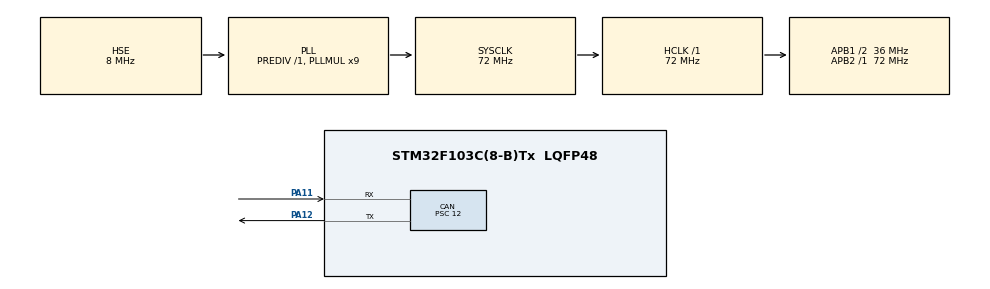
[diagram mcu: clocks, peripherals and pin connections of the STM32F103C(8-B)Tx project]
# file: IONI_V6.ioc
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CAN.CalculateBaudRate=999999
CAN.CalculateTimeBit=1000
CAN.CalculateTimeQuantum=333.33333333333337
CAN.Mode=CAN_MODE_NORMAL
CAN.Prescaler=12
Mcu.Family=STM32F1
Mcu.Name=STM32F103C(8-B)Tx
Mcu.Package=LQFP48
NVIC.CAN1_RX1_IRQn=true\:0\:0\:false\:false\:true\:true\:true\:true
NVIC.PriorityGroup=NVIC_PRIORITYGROUP_4
NVIC.USB_LP_CAN1_RX0_IRQn=true\:0\:0\:false\:false\:true\:true\:true\:true
PA11.Mode=CAN_Activate
PA11.Signal=CAN_RX
PA12.Mode=CAN_Activate
PA12.Signal=CAN_TX
PA13.Mode=Serial_Wire
PA13.Signal=SYS_JTMS-SWDIO
PA14.Mode=Serial_Wire
PA14.Signal=SYS_JTCK-SWCLK
PD0-OSC_IN.Mode=HSE-External-Oscillator
PD0-OSC_IN.Signal=RCC_OSC_IN
PD1-OSC_OUT.Mode=HSE-External-Oscillator
PD1-OSC_OUT.Signal=RCC_OSC_OUT
ProjectManager.HeapSize=0x200
ProjectManager.StackSize=0x400
ProjectManager.TargetToolchain=STM32CubeIDE
RCC.AHBFreq_Value=72000000
RCC.APB1CLKDivider=RCC_HCLK_DIV2
RCC.APB1Freq_Value=36000000
RCC.APB1TimFreq_Value=72000000
RCC.APB2Freq_Value=72000000
RCC.APB2TimFreq_Value=72000000
RCC.HCLKFreq_Value=72000000
RCC.PLLMUL=RCC_PLL_MUL9
RCC.PLLSourceVirtual=RCC_PLLSOURCE_HSE
RCC.SYSCLKFreq_VALUE=72000000
RCC.SYSCLKSource=RCC_SYSCLKSOURCE_PLLCLK
RCC.USBFreq_Value=72000000
board=custom

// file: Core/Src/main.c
/* USER CODE BEGIN Header */
/**
now i am updated this using fork technology.
  ******************************************************************************
  * @file           : main.c
  * @brief          : Main program body
  ******************************************************************************
  * @attention
  *
  * <h2><center>&copy; Copyright (c) 2024 STMicroelectronics.
  * All rights reserved.</center></h2>
  *
  * This software component is licensed by ST under BSD 3-Clause license,
  * the "License"; You may not use this file except in compliance with the
  * License. You may obtain a copy of the License at:
  *                        opensource.org/licenses/BSD-3-Clause
  *
  ******************************************************************************
  */
/* USER CODE END Header */
#include "main.h"

/* USER CODE BEGIN Includes */

#include "can.h"

/* USER CODE END Includes */

CAN_HandleTypeDef hcan;

/* USER CODE BEGIN PV */

CAN_HandleTypeDef hcan; // Declare hcan as extern here

extern BytesUnion rxDataUnion;

float currentPosition = 12.345; // Example position
float currentSpeed = 123.45; // Example speed

/* USER CODE END PV */

void SystemClock_Config(void);
static void MX_GPIO_Init(void);
static void MX_CAN_Init(void);

/* USER CODE BEGIN 0 */

void ProcessReceivedMessage(void) {
    received_flag = 0;

    // Handle the received message
	if (rxHeader.StdId == 0x610) {
		uint8_t command = rxDataUnion.bytes[1];
		// Check specific commands in the received data
		switch (command) {
		case 0x45:
			// Command to get current target position (absolute value)
			break;
		case 0x44:
			// Command to set target position (incremental)
			break;
		case 0x50:
			// Command to start homing
			break;
		case 0x51:
			// Command to stop homing
			break;
		case 0x52:
			// Command to stop
			break;
		case 0x00:
			// Command to quick stop
			break;
		default:
			// Unknown command, handle appropriately
			break;
		}
	}
}

/* USER CODE END 0 */

int main(void)
{

  /* MCU Configuration--------------------------------------------------------*/

  /* Reset of all peripherals, Initializes the Flash interface and the Systick. */
  HAL_Init();

  /* Configure the system clock */
  SystemClock_Config();

  /* Initialize all configured peripherals */
  MX_GPIO_Init();
  MX_CAN_Init();
  /* USER CODE BEGIN 2 */

  HAL_CAN_Start(&hcan);

//  // Start CAN receive interrupt callback
//  HAL_CAN_ActivateNotification(&hcan, CAN_IT_RX_FIFO0_MSG_PENDING);

  /* USER CODE END 2 */

  /* Infinite loop */
  while (1)
  {

    /* USER CODE BEGIN 3 */

	  // Transmit Position and Speed periodically
	  SendPosition(currentPosition);
	  HAL_Delay(100); // Delay to avoid bus congestion

	  // Check if a message is received
	  if (CheckCANMessage()) {
		  ProcessReceivedMessage();
	  }

  }
  /* USER CODE END 3 */
}

void SystemClock_Config(void)
{
  RCC_OscInitTypeDef RCC_OscInitStruct = {0};
  RCC_ClkInitTypeDef RCC_ClkInitStruct = {0};

  /** Initializes the RCC Oscillators according to the specified parameters
  * in the RCC_OscInitTypeDef structure.
  */
  RCC_OscInitStruct.OscillatorType = RCC_OSCILLATORTYPE_HSE;
  RCC_OscInitStruct.HSEState = RCC_HSE_ON;
  RCC_OscInitStruct.HSEPredivValue = RCC_HSE_PREDIV_DIV1;
  RCC_OscInitStruct.HSIState = RCC_HSI_ON;
  RCC_OscInitStruct.PLL.PLLState = RCC_PLL_ON;
  RCC_OscInitStruct.PLL.PLLSource = RCC_PLLSOURCE_HSE;
  RCC_OscInitStruct.PLL.PLLMUL = RCC_PLL_MUL9;
  if (HAL_RCC_OscConfig(&RCC_OscInitStruct) != HAL_OK)
  {
    Error_Handler();
  }
  /** Initializes the CPU, AHB and APB buses clocks
  */
  RCC_ClkInitStruct.ClockType = RCC_CLOCKTYPE_HCLK|RCC_CLOCKTYPE_SYSCLK
                              |RCC_CLOCKTYPE_PCLK1|RCC_CLOCKTYPE_PCLK2;
  RCC_ClkInitStruct.SYSCLKSource = RCC_SYSCLKSOURCE_PLLCLK;
  RCC_ClkInitStruct.AHBCLKDivider = RCC_SYSCLK_DIV1;
  RCC_ClkInitStruct.APB1CLKDivider = RCC_HCLK_DIV2;
  RCC_ClkInitStruct.APB2CLKDivider = RCC_HCLK_DIV1;

  if (HAL_RCC_ClockConfig(&RCC_ClkInitStruct, FLASH_LATENCY_2) != HAL_OK)
  {
    Error_Handler();
  }
}

static void MX_CAN_Init(void)
{

  hcan.Instance = CAN1;
  hcan.Init.Prescaler = 12;
  hcan.Init.Mode = CAN_MODE_NORMAL;
  hcan.Init.SyncJumpWidth = CAN_SJW_1TQ;
  hcan.Init.TimeSeg1 = CAN_BS1_1TQ;
  hcan.Init.TimeSeg2 = CAN_BS2_1TQ;
  hcan.Init.TimeTriggeredMode = DISABLE;
  hcan.Init.AutoBusOff = DISABLE;
  hcan.Init.AutoWakeUp = DISABLE;
  hcan.Init.AutoRetransmission = DISABLE;
  hcan.Init.ReceiveFifoLocked = DISABLE;
  hcan.Init.TransmitFifoPriority = DISABLE;
  if (HAL_CAN_Init(&hcan) != HAL_OK)
  {
    Error_Handler();
  }
  /* USER CODE BEGIN CAN_Init 2 */

  // Configure CAN filters
    CAN_FilterTypeDef canfilterconfig;
    canfilterconfig.FilterActivation = CAN_FILTER_ENABLE;
    canfilterconfig.FilterBank = 0;
    canfilterconfig.FilterFIFOAssignment = CAN_FILTER_FIFO0;
    canfilterconfig.FilterIdHigh = 0x610 << 5;
    canfilterconfig.FilterIdLow = 0x0000;
    canfilterconfig.FilterMaskIdHigh = 0x610 << 5;
    canfilterconfig.FilterMaskIdLow = 0x0000;
    canfilterconfig.FilterMode = CAN_FILTERMODE_IDMASK;
    canfilterconfig.FilterScale = CAN_FILTERSCALE_32BIT;
    canfilterconfig.FilterBank = 0;
    HAL_CAN_ConfigFilter(&hcan, &canfilterconfig);

    // Start the CAN peripheral
    if (HAL_CAN_Start(&hcan) != HAL_OK)
    {
      Error_Handler();
    }

    // Activate CAN RX notification
    HAL_CAN_ActivateNotification(&hcan, CAN_IT_RX_FIFO0_MSG_PENDING);

  /* USER CODE END CAN_Init 2 */

}

static void MX_GPIO_Init(void)
{

  /* GPIO Ports Clock Enable */
  __HAL_RCC_GPIOD_CLK_ENABLE();
  __HAL_RCC_GPIOA_CLK_ENABLE();

}

void Error_Handler(void)
{
  __disable_irq();
  while (1)
  {
  }
}

/************************ (C) COPYRIGHT STMicroelectronics *****END OF FILE****/
